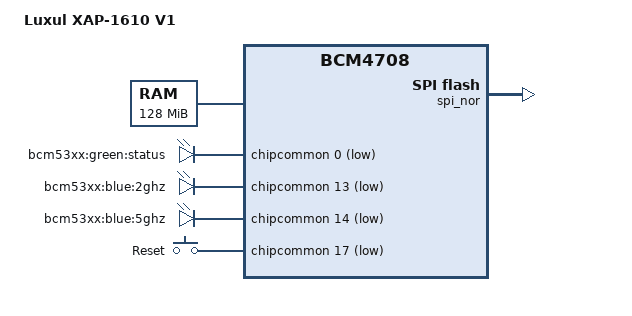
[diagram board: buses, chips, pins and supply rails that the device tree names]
// SPDX-License-Identifier: GPL-2.0-or-later OR MIT
/*
 * Copyright 2018 Luxul Inc.
 */

/dts-v1/;

#include "bcm47094.dtsi"

/ {
	compatible = "luxul,xap-1610-v1", "brcm,bcm47094", "brcm,bcm4708";
	model = "Luxul XAP-1610 V1";

	chosen {
		bootargs = "earlycon";
	};

	memory {
		reg = <0x00000000 0x08000000>;
	};

	leds {
		compatible = "gpio-leds";

		status	{
			label = "bcm53xx:green:status";
			gpios = <&chipcommon 0 GPIO_ACTIVE_LOW>;
			linux,default-trigger = "timer";
		};

		2ghz {
			label = "bcm53xx:blue:2ghz";
			gpios = <&chipcommon 13 GPIO_ACTIVE_LOW>;
		};

		5ghz {
			label = "bcm53xx:blue:5ghz";
			gpios = <&chipcommon 14 GPIO_ACTIVE_LOW>;
		};
	};

	gpio-keys {
		compatible = "gpio-keys";
		#address-cells = <1>;
		#size-cells = <0>;

		restart {
			label = "Reset";
			linux,code = <KEY_RESTART>;
			gpios = <&chipcommon 17 GPIO_ACTIVE_LOW>;
		};
	};
};

&spi_nor {
	status = "okay";
};
